# MIMXRT1064 register map
Vendor: nxp.com; File version: 1.0
CPU: CM7 r0p1, little endian, MPU, FPU, VTOR, 4 interrupt priority bits
Registers are 32-bit, read-write, reset 0x0 unless marked. A register's access mark holds for its fields unless they carry their own. Offsets are from the block's base; [hi:lo] are bit positions; 'fields as' and 'values as' point back to an identical list.

## USBPHY1 — USBPHY Register Reference Index
Base 0x400D9000; register names take the prefix USBPHY1_
Same registers: USBPHY2 0x400DA000 (register names take the prefix USBPHY2_)
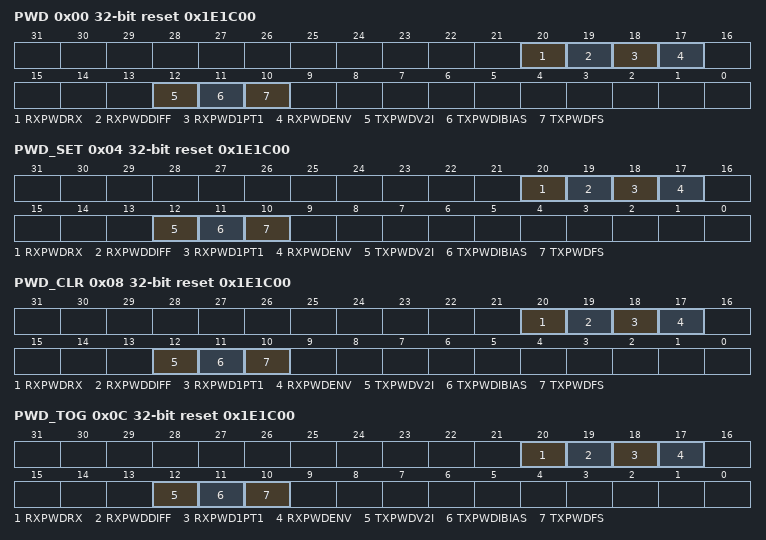
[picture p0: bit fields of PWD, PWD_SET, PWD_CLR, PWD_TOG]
0x00 PWD reset 0x1E1C00 — USB PHY Power-Down Register
  [20] RXPWDRX — 0 = Normal operation
  [19] RXPWDDIFF — 0 = Normal operation
  [18] RXPWD1PT1 — 0 = Normal operation
  [17] RXPWDENV — 0 = Normal operation
  [12] TXPWDV2I — 0 = Normal operation
  [11] TXPWDIBIAS — 0 = Normal operation
  [10] TXPWDFS — 0 = Normal operation
0x04 PWD_SET reset 0x1E1C00 — USB PHY Power-Down Register
  fields as PWD
0x08 PWD_CLR reset 0x1E1C00 — USB PHY Power-Down Register
  fields as PWD
0x0C PWD_TOG reset 0x1E1C00 — USB PHY Power-Down Register
  fields as PWD
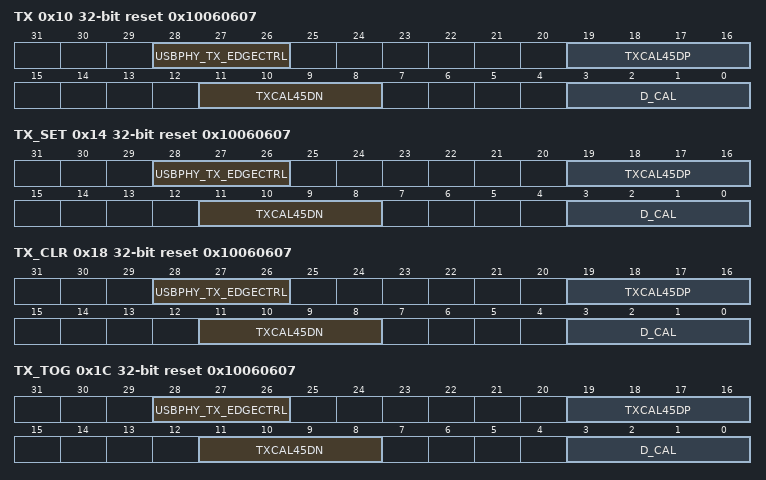
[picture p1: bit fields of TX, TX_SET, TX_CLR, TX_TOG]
0x10 TX reset 0x10060607 — USB PHY Transmitter Control Register
  [28:26] USBPHY_TX_EDGECTRL — Controls the edge-rate of the current sensing transistors used in HS transmit
  [19:16] TXCAL45DP — Decode to select a 45-Ohm resistance to the USB_DP output pin
  [11:8] TXCAL45DN — Decode to select a 45-Ohm resistance to the USB_DN output pin
  [3:0] D_CAL — Resistor Trimming Code: 0000 = 0.16% 0111 = Nominal 1111 = +25%
0x14 TX_SET reset 0x10060607 — USB PHY Transmitter Control Register
  fields as TX
0x18 TX_CLR reset 0x10060607 — USB PHY Transmitter Control Register
  fields as TX
0x1C TX_TOG reset 0x10060607 — USB PHY Transmitter Control Register
  fields as TX
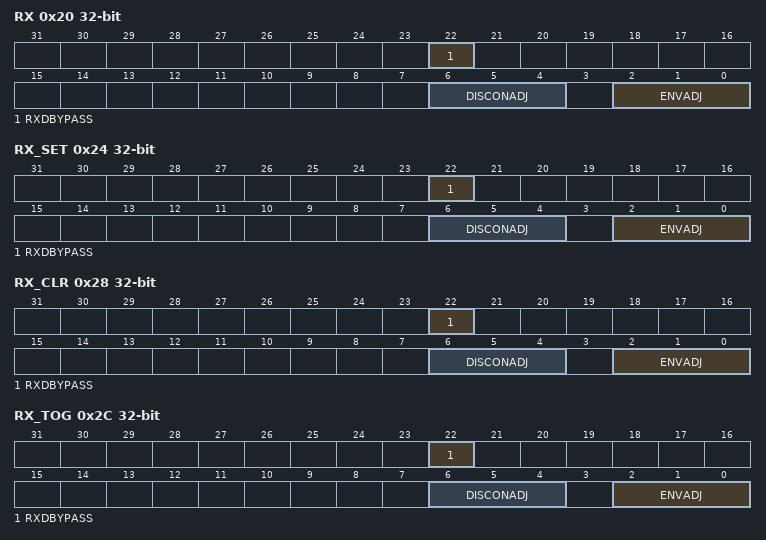
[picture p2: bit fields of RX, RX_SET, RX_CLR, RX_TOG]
0x20 RX — USB PHY Receiver Control Register
  [22] RXDBYPASS — 0 = Normal operation
  [6:4] DISCONADJ — The DISCONADJ field adjusts the trip point for the disconnect detector: 000 = Trip-Level Voltage is 0
  [2:0] ENVADJ — The ENVADJ field adjusts the trip point for the envelope detector
0x24 RX_SET — USB PHY Receiver Control Register
  fields as RX
0x28 RX_CLR — USB PHY Receiver Control Register
  fields as RX
0x2C RX_TOG — USB PHY Receiver Control Register
  fields as RX
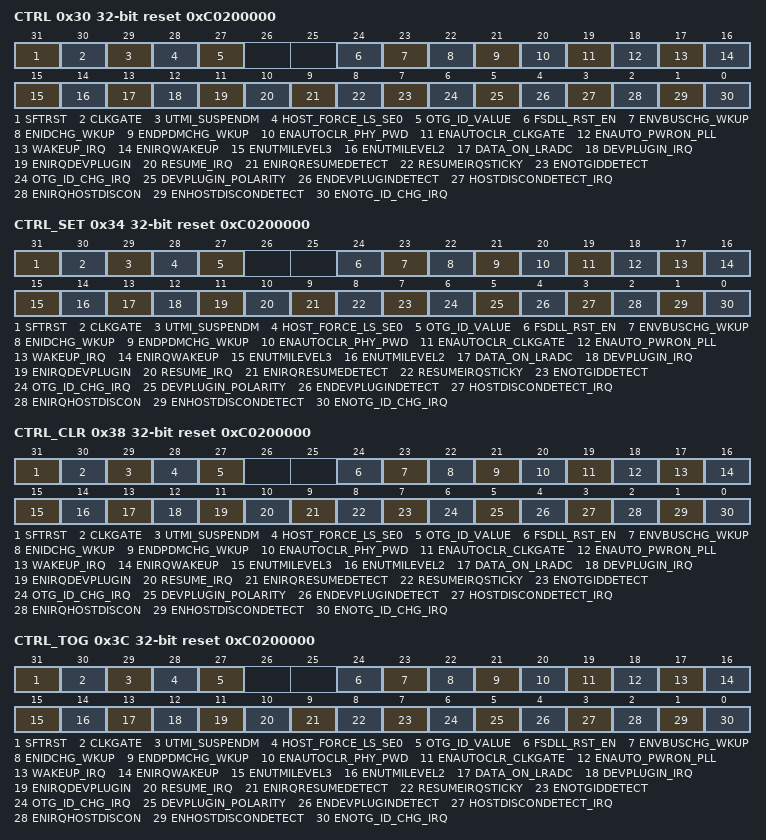
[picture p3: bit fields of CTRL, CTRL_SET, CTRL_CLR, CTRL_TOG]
0x30 CTRL reset 0xC0200000 — USB PHY General Control Register
  [31] SFTRST — Writing a 1 to this bit will soft-reset the USBPHYx_PWD, USBPHYx_TX, USBPHYx_RX, and USBPHYx_CTRL registers
  [30] CLKGATE — Gate UTMI Clocks
  [29] UTMI_SUSPENDM ro — Used by the PHY to indicate a powered-down state
  [28] HOST_FORCE_LS_SE0 — Forces the next FS packet that is transmitted to have a EOP with LS timing
  [27] OTG_ID_VALUE ro — Almost same as OTGID_STATUS in USBPHYx_STATUS Register
  [24] FSDLL_RST_EN — Enables the feature to reset the FSDLL lock detection logic at the end of each TX packet.
  [23] ENVBUSCHG_WKUP — Enables the feature to wakeup USB if VBUS is toggled when USB is suspended.
  [22] ENIDCHG_WKUP — Enables the feature to wakeup USB if ID is toggled when USB is suspended.
  [21] ENDPDMCHG_WKUP — Enables the feature to wakeup USB if DP/DM is toggled when USB is suspended
  [20] ENAUTOCLR_PHY_PWD — Enables the feature to auto-clear the PWD register bits in USBPHYx_PWD if there is wakeup event while USB is suspended
  [19] ENAUTOCLR_CLKGATE — Enables the feature to auto-clear the CLKGATE bit if there is wakeup event while USB is suspended
  [18] ENAUTO_PWRON_PLL — Enables the feature to auto-enable the POWER bit of HW_CLKCTRL_PLLxCTRL0 if there is wakeup event if USB is suspended
  [17] WAKEUP_IRQ — Indicates that there is a wakeup event
  [16] ENIRQWAKEUP — Enables interrupt for the wakeup events.
  [15] ENUTMILEVEL3 — Enables UTMI+ Level3
  [14] ENUTMILEVEL2 — Enables UTMI+ Level2. This should be enabled if needs to support LS device
  [13] DATA_ON_LRADC — Enables the LRADC to monitor USB_DP and USB_DM. This is for use in non-USB modes only.
  [12] DEVPLUGIN_IRQ — Indicates that the device is connected
  [11] ENIRQDEVPLUGIN — Enables interrupt for the detection of connectivity to the USB line.
  [10] RESUME_IRQ — Indicates that the host is sending a wake-up after suspend
  [9] ENIRQRESUMEDETECT — Enables interrupt for detection of a non-J state on the USB line
  [8] RESUMEIRQSTICKY — Set to 1 will make RESUME_IRQ bit a sticky bit until software clear it
  [7] ENOTGIDDETECT — Enables circuit to detect resistance of MiniAB ID pin.
  [6] OTG_ID_CHG_IRQ — OTG ID change interrupt. Indicates the value of ID pin changed.
  [5] DEVPLUGIN_POLARITY — For device mode, if this bit is cleared to 0, then it trips the interrupt if the device is plugged in
  [4] ENDEVPLUGINDETECT — For device mode, enables 200-KOhm pullups for detecting connectivity to the host.
  [3] HOSTDISCONDETECT_IRQ — Indicates that the device has disconnected in high-speed mode
  [2] ENIRQHOSTDISCON — Enables interrupt for detection of disconnection to Device when in high-speed host mode
  [1] ENHOSTDISCONDETECT — For host mode, enables high-speed disconnect detector
  [0] ENOTG_ID_CHG_IRQ — Enable OTG_ID_CHG_IRQ.
0x34 CTRL_SET reset 0xC0200000 — USB PHY General Control Register
  fields as CTRL
0x38 CTRL_CLR reset 0xC0200000 — USB PHY General Control Register
  fields as CTRL
0x3C CTRL_TOG reset 0xC0200000 — USB PHY General Control Register
  fields as CTRL
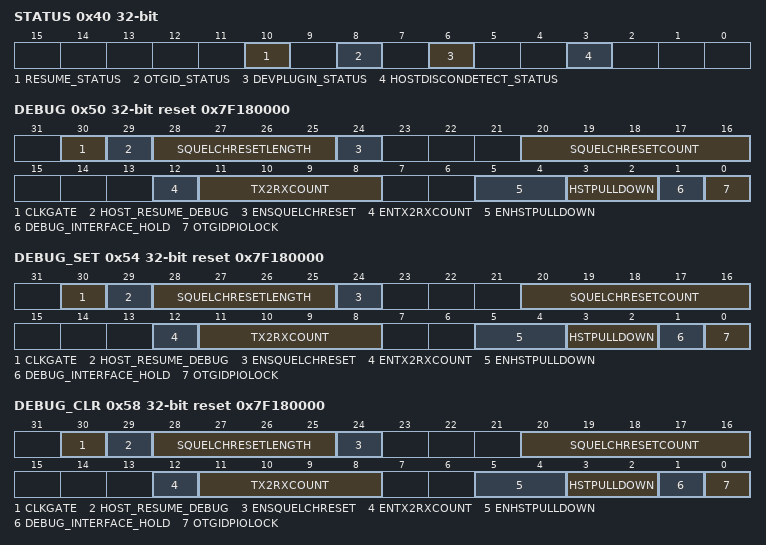
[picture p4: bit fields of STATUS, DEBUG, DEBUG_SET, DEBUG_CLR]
0x40 STATUS — USB PHY Status Register
  [10] RESUME_STATUS ro — Indicates that the host is sending a wake-up after suspend and has triggered an interrupt.
  [8] OTGID_STATUS — Indicates the results of ID pin on MiniAB plug
  [6] DEVPLUGIN_STATUS ro — Indicates that the device has been connected on the USB_DP and USB_DM lines.
  [3] HOSTDISCONDETECT_STATUS ro — Indicates that the device has disconnected while in high-speed host mode.
0x50 DEBUG reset 0x7F180000 — USB PHY Debug Register
  [30] CLKGATE — Gate Test Clocks
  [29] HOST_RESUME_DEBUG — Choose to trigger the host resume SE0 with HOST_FORCE_LS_SE0 = 0 or UTMI_SUSPEND = 1.
  [28:25] SQUELCHRESETLENGTH — Duration of RESET in terms of the number of 480-MHz cycles.
  [24] ENSQUELCHRESET — Set bit to allow squelch to reset high-speed receive.
  [20:16] SQUELCHRESETCOUNT — Delay in between the detection of squelch to the reset of high-speed RX.
  [12] ENTX2RXCOUNT — Set this bit to allow a countdown to transition in between TX and RX.
  [11:8] TX2RXCOUNT — Delay in between the end of transmit to the beginning of receive
  [5:4] ENHSTPULLDOWN — Set bit 5 to 1 to override the control of the USB_DP 15-KOhm pulldown
  [3:2] HSTPULLDOWN — Set bit 3 to 1 to pull down 15-KOhm on USB_DP line
  [1] DEBUG_INTERFACE_HOLD — Use holding registers to assist in timing for external UTMI interface.
  [0] OTGIDPIOLOCK — Once OTG ID from USBPHYx_STATUS_OTGID_STATUS, use this to hold the value
0x54 DEBUG_SET reset 0x7F180000 — USB PHY Debug Register
  fields as DEBUG
0x58 DEBUG_CLR reset 0x7F180000 — USB PHY Debug Register
  fields as DEBUG
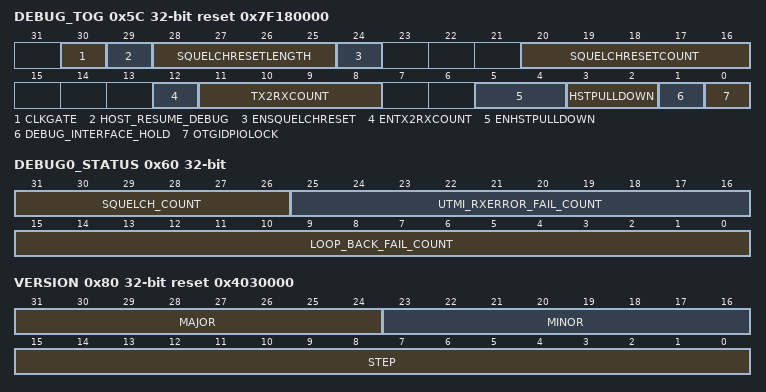
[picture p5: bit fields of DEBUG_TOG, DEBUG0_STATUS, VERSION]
0x5C DEBUG_TOG reset 0x7F180000 — USB PHY Debug Register
  fields as DEBUG
0x60 DEBUG0_STATUS ro — UTMI Debug Status Register 0
  [31:26] SQUELCH_COUNT — Running count of the squelch reset instead of normal end for HS RX.
  [25:16] UTMI_RXERROR_FAIL_COUNT — Running count of the UTMI_RXERROR.
  [15:0] LOOP_BACK_FAIL_COUNT — Running count of the failed pseudo-random generator loopback
0x70 DEBUG1 reset 0x1000 — UTMI Debug Status Register 1
  [14:13] ENTAILADJVD — Delay increment of the rise of squelch: 00 = Delay is nominal 01 = Delay is +20% 10 = Delay is -20% 11 = Delay is -40%
0x74 DEBUG1_SET reset 0x1000 — UTMI Debug Status Register 1
  fields as DEBUG1
0x78 DEBUG1_CLR reset 0x1000 — UTMI Debug Status Register 1
  fields as DEBUG1
0x7C DEBUG1_TOG reset 0x1000 — UTMI Debug Status Register 1
  fields as DEBUG1
0x80 VERSION ro reset 0x4030000 — UTMI RTL Version
  [31:24] MAJOR — Fixed read-only value reflecting the MAJOR field of the RTL version.
  [23:16] MINOR — Fixed read-only value reflecting the MINOR field of the RTL version.
  [15:0] STEP — Fixed read-only value reflecting the stepping of the RTL version.

## Notices in the file
Copyright 2016-2022 NXP
All rights reserved.
SPDX-License-Identifier: BSD-3-Clause
